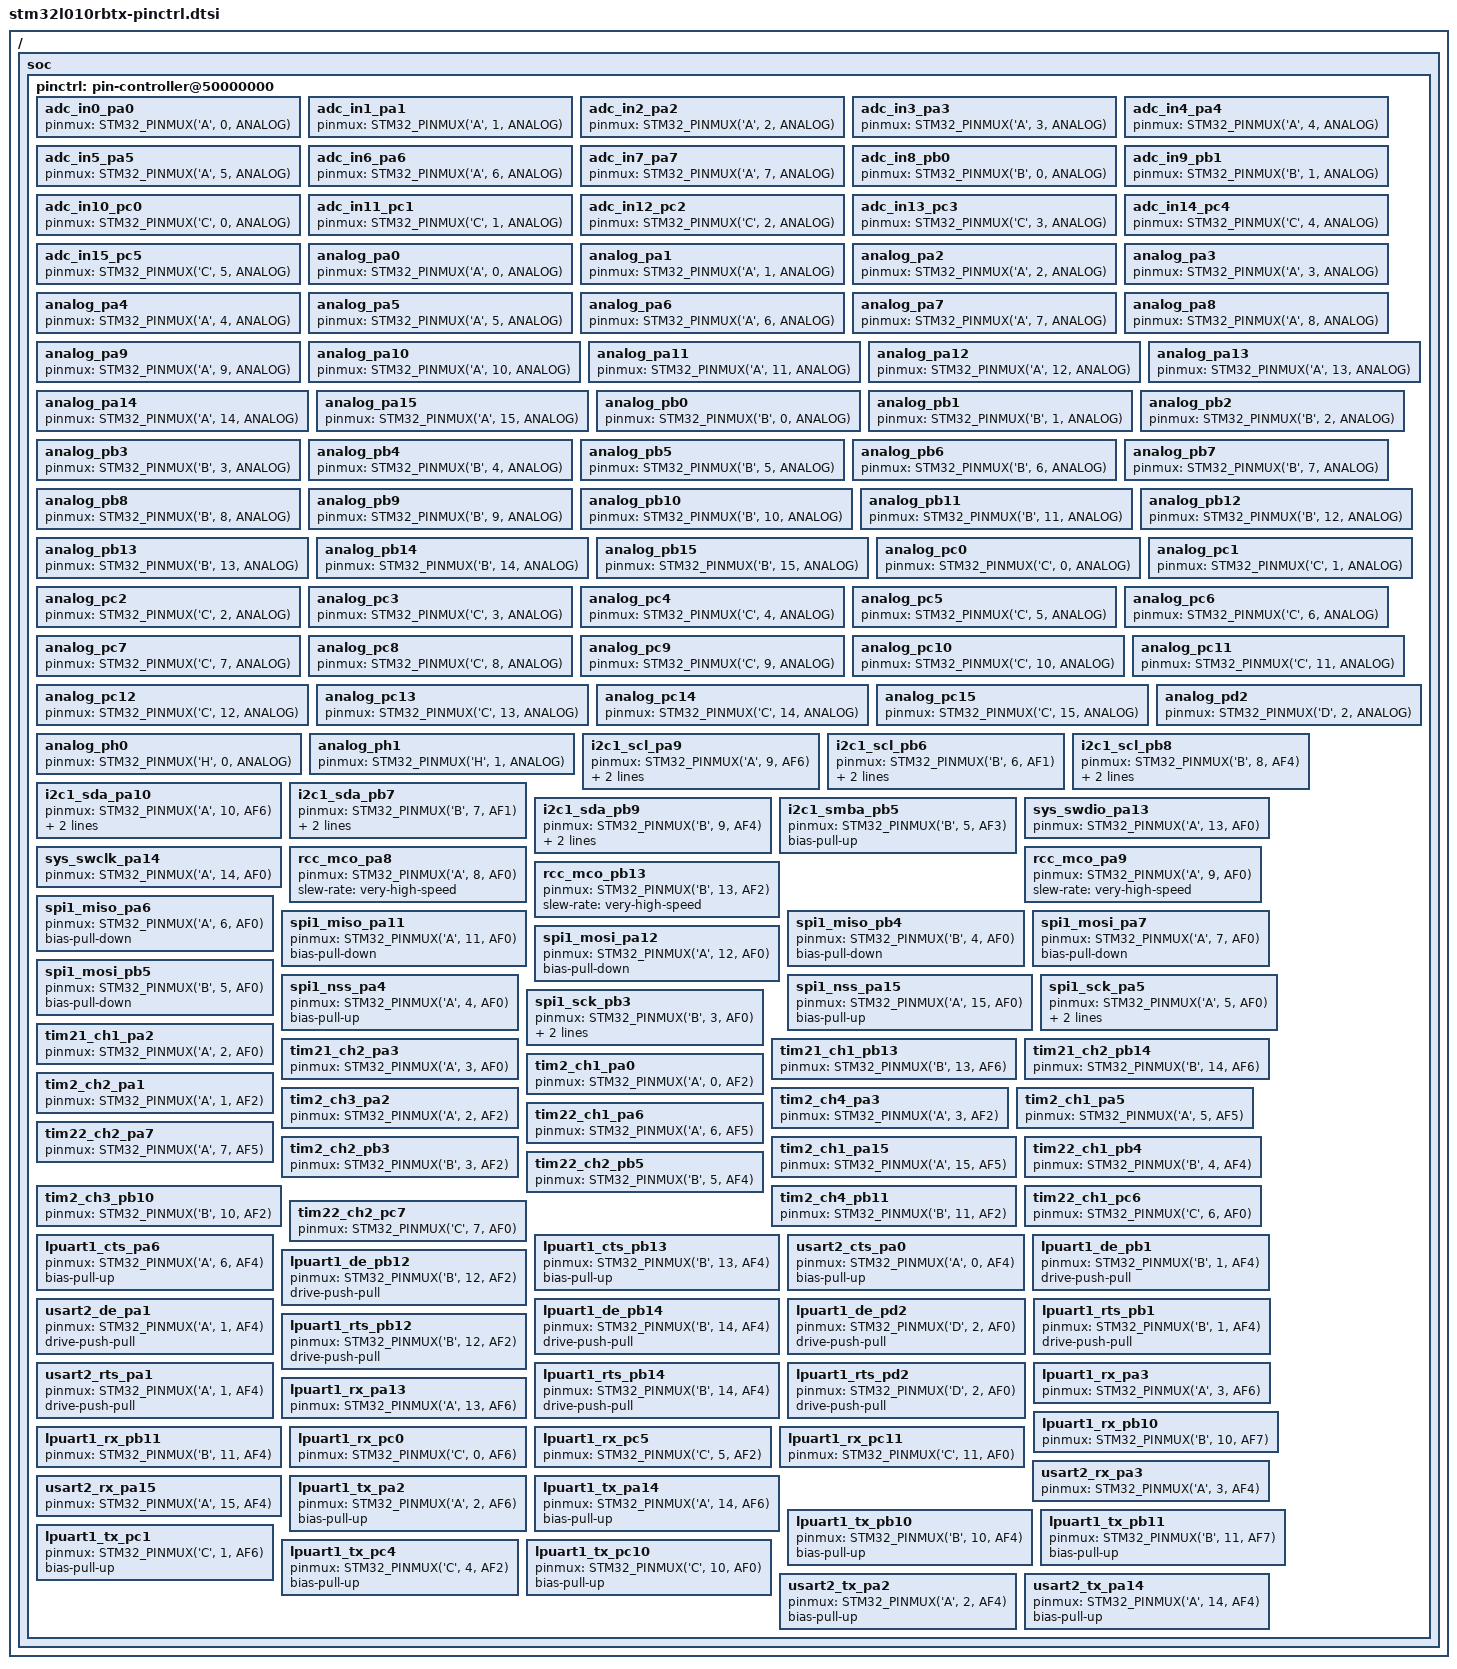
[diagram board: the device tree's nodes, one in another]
/*
 * NOTE: Autogenerated file using genpinctrl.py
 *
 * SPDX-License-Identifier: Apache-2.0
 */

#include <zephyr/dt-bindings/pinctrl/stm32-pinctrl.h>

/ {
	soc {
		pinctrl: pin-controller@50000000 {

			/* ADC_IN / ADC_INN / ADC_INP */

			/omit-if-no-ref/ adc_in0_pa0: adc_in0_pa0 {
				pinmux = <STM32_PINMUX('A', 0, ANALOG)>;
			};

			/omit-if-no-ref/ adc_in1_pa1: adc_in1_pa1 {
				pinmux = <STM32_PINMUX('A', 1, ANALOG)>;
			};

			/omit-if-no-ref/ adc_in2_pa2: adc_in2_pa2 {
				pinmux = <STM32_PINMUX('A', 2, ANALOG)>;
			};

			/omit-if-no-ref/ adc_in3_pa3: adc_in3_pa3 {
				pinmux = <STM32_PINMUX('A', 3, ANALOG)>;
			};

			/omit-if-no-ref/ adc_in4_pa4: adc_in4_pa4 {
				pinmux = <STM32_PINMUX('A', 4, ANALOG)>;
			};

			/omit-if-no-ref/ adc_in5_pa5: adc_in5_pa5 {
				pinmux = <STM32_PINMUX('A', 5, ANALOG)>;
			};

			/omit-if-no-ref/ adc_in6_pa6: adc_in6_pa6 {
				pinmux = <STM32_PINMUX('A', 6, ANALOG)>;
			};

			/omit-if-no-ref/ adc_in7_pa7: adc_in7_pa7 {
				pinmux = <STM32_PINMUX('A', 7, ANALOG)>;
			};

			/omit-if-no-ref/ adc_in8_pb0: adc_in8_pb0 {
				pinmux = <STM32_PINMUX('B', 0, ANALOG)>;
			};

			/omit-if-no-ref/ adc_in9_pb1: adc_in9_pb1 {
				pinmux = <STM32_PINMUX('B', 1, ANALOG)>;
			};

			/omit-if-no-ref/ adc_in10_pc0: adc_in10_pc0 {
				pinmux = <STM32_PINMUX('C', 0, ANALOG)>;
			};

			/omit-if-no-ref/ adc_in11_pc1: adc_in11_pc1 {
				pinmux = <STM32_PINMUX('C', 1, ANALOG)>;
			};

			/omit-if-no-ref/ adc_in12_pc2: adc_in12_pc2 {
				pinmux = <STM32_PINMUX('C', 2, ANALOG)>;
			};

			/omit-if-no-ref/ adc_in13_pc3: adc_in13_pc3 {
				pinmux = <STM32_PINMUX('C', 3, ANALOG)>;
			};

			/omit-if-no-ref/ adc_in14_pc4: adc_in14_pc4 {
				pinmux = <STM32_PINMUX('C', 4, ANALOG)>;
			};

			/omit-if-no-ref/ adc_in15_pc5: adc_in15_pc5 {
				pinmux = <STM32_PINMUX('C', 5, ANALOG)>;
			};

			/* Analog */

			/omit-if-no-ref/ analog_pa0: analog_pa0 {
				pinmux = <STM32_PINMUX('A', 0, ANALOG)>;
			};

			/omit-if-no-ref/ analog_pa1: analog_pa1 {
				pinmux = <STM32_PINMUX('A', 1, ANALOG)>;
			};

			/omit-if-no-ref/ analog_pa2: analog_pa2 {
				pinmux = <STM32_PINMUX('A', 2, ANALOG)>;
			};

			/omit-if-no-ref/ analog_pa3: analog_pa3 {
				pinmux = <STM32_PINMUX('A', 3, ANALOG)>;
			};

			/omit-if-no-ref/ analog_pa4: analog_pa4 {
				pinmux = <STM32_PINMUX('A', 4, ANALOG)>;
			};

			/omit-if-no-ref/ analog_pa5: analog_pa5 {
				pinmux = <STM32_PINMUX('A', 5, ANALOG)>;
			};

			/omit-if-no-ref/ analog_pa6: analog_pa6 {
				pinmux = <STM32_PINMUX('A', 6, ANALOG)>;
			};

			/omit-if-no-ref/ analog_pa7: analog_pa7 {
				pinmux = <STM32_PINMUX('A', 7, ANALOG)>;
			};

			/omit-if-no-ref/ analog_pa8: analog_pa8 {
				pinmux = <STM32_PINMUX('A', 8, ANALOG)>;
			};

			/omit-if-no-ref/ analog_pa9: analog_pa9 {
				pinmux = <STM32_PINMUX('A', 9, ANALOG)>;
			};

			/omit-if-no-ref/ analog_pa10: analog_pa10 {
				pinmux = <STM32_PINMUX('A', 10, ANALOG)>;
			};

			/omit-if-no-ref/ analog_pa11: analog_pa11 {
				pinmux = <STM32_PINMUX('A', 11, ANALOG)>;
			};

			/omit-if-no-ref/ analog_pa12: analog_pa12 {
				pinmux = <STM32_PINMUX('A', 12, ANALOG)>;
			};

			/omit-if-no-ref/ analog_pa13: analog_pa13 {
				pinmux = <STM32_PINMUX('A', 13, ANALOG)>;
			};

			/omit-if-no-ref/ analog_pa14: analog_pa14 {
				pinmux = <STM32_PINMUX('A', 14, ANALOG)>;
			};

			/omit-if-no-ref/ analog_pa15: analog_pa15 {
				pinmux = <STM32_PINMUX('A', 15, ANALOG)>;
			};

			/omit-if-no-ref/ analog_pb0: analog_pb0 {
				pinmux = <STM32_PINMUX('B', 0, ANALOG)>;
			};

			/omit-if-no-ref/ analog_pb1: analog_pb1 {
				pinmux = <STM32_PINMUX('B', 1, ANALOG)>;
			};

			/omit-if-no-ref/ analog_pb2: analog_pb2 {
				pinmux = <STM32_PINMUX('B', 2, ANALOG)>;
			};

			/omit-if-no-ref/ analog_pb3: analog_pb3 {
				pinmux = <STM32_PINMUX('B', 3, ANALOG)>;
			};

			/omit-if-no-ref/ analog_pb4: analog_pb4 {
				pinmux = <STM32_PINMUX('B', 4, ANALOG)>;
			};

			/omit-if-no-ref/ analog_pb5: analog_pb5 {
				pinmux = <STM32_PINMUX('B', 5, ANALOG)>;
			};

			/omit-if-no-ref/ analog_pb6: analog_pb6 {
				pinmux = <STM32_PINMUX('B', 6, ANALOG)>;
			};

			/omit-if-no-ref/ analog_pb7: analog_pb7 {
				pinmux = <STM32_PINMUX('B', 7, ANALOG)>;
			};

			/omit-if-no-ref/ analog_pb8: analog_pb8 {
				pinmux = <STM32_PINMUX('B', 8, ANALOG)>;
			};

			/omit-if-no-ref/ analog_pb9: analog_pb9 {
				pinmux = <STM32_PINMUX('B', 9, ANALOG)>;
			};

			/omit-if-no-ref/ analog_pb10: analog_pb10 {
				pinmux = <STM32_PINMUX('B', 10, ANALOG)>;
			};

			/omit-if-no-ref/ analog_pb11: analog_pb11 {
				pinmux = <STM32_PINMUX('B', 11, ANALOG)>;
			};

			/omit-if-no-ref/ analog_pb12: analog_pb12 {
				pinmux = <STM32_PINMUX('B', 12, ANALOG)>;
			};

			/omit-if-no-ref/ analog_pb13: analog_pb13 {
				pinmux = <STM32_PINMUX('B', 13, ANALOG)>;
			};

			/omit-if-no-ref/ analog_pb14: analog_pb14 {
				pinmux = <STM32_PINMUX('B', 14, ANALOG)>;
			};

			/omit-if-no-ref/ analog_pb15: analog_pb15 {
				pinmux = <STM32_PINMUX('B', 15, ANALOG)>;
			};

			/omit-if-no-ref/ analog_pc0: analog_pc0 {
				pinmux = <STM32_PINMUX('C', 0, ANALOG)>;
			};

			/omit-if-no-ref/ analog_pc1: analog_pc1 {
				pinmux = <STM32_PINMUX('C', 1, ANALOG)>;
			};

			/omit-if-no-ref/ analog_pc2: analog_pc2 {
				pinmux = <STM32_PINMUX('C', 2, ANALOG)>;
			};

			/omit-if-no-ref/ analog_pc3: analog_pc3 {
				pinmux = <STM32_PINMUX('C', 3, ANALOG)>;
			};

			/omit-if-no-ref/ analog_pc4: analog_pc4 {
				pinmux = <STM32_PINMUX('C', 4, ANALOG)>;
			};

			/omit-if-no-ref/ analog_pc5: analog_pc5 {
				pinmux = <STM32_PINMUX('C', 5, ANALOG)>;
			};

			/omit-if-no-ref/ analog_pc6: analog_pc6 {
				pinmux = <STM32_PINMUX('C', 6, ANALOG)>;
			};

			/omit-if-no-ref/ analog_pc7: analog_pc7 {
				pinmux = <STM32_PINMUX('C', 7, ANALOG)>;
			};

			/omit-if-no-ref/ analog_pc8: analog_pc8 {
				pinmux = <STM32_PINMUX('C', 8, ANALOG)>;
			};

			/omit-if-no-ref/ analog_pc9: analog_pc9 {
				pinmux = <STM32_PINMUX('C', 9, ANALOG)>;
			};

			/omit-if-no-ref/ analog_pc10: analog_pc10 {
				pinmux = <STM32_PINMUX('C', 10, ANALOG)>;
			};

			/omit-if-no-ref/ analog_pc11: analog_pc11 {
				pinmux = <STM32_PINMUX('C', 11, ANALOG)>;
			};

			/omit-if-no-ref/ analog_pc12: analog_pc12 {
				pinmux = <STM32_PINMUX('C', 12, ANALOG)>;
			};

			/omit-if-no-ref/ analog_pc13: analog_pc13 {
				pinmux = <STM32_PINMUX('C', 13, ANALOG)>;
			};

			/omit-if-no-ref/ analog_pc14: analog_pc14 {
				pinmux = <STM32_PINMUX('C', 14, ANALOG)>;
			};

			/omit-if-no-ref/ analog_pc15: analog_pc15 {
				pinmux = <STM32_PINMUX('C', 15, ANALOG)>;
			};

			/omit-if-no-ref/ analog_pd2: analog_pd2 {
				pinmux = <STM32_PINMUX('D', 2, ANALOG)>;
			};

			/omit-if-no-ref/ analog_ph0: analog_ph0 {
				pinmux = <STM32_PINMUX('H', 0, ANALOG)>;
			};

			/omit-if-no-ref/ analog_ph1: analog_ph1 {
				pinmux = <STM32_PINMUX('H', 1, ANALOG)>;
			};

			/* I2C_SCL */

			/omit-if-no-ref/ i2c1_scl_pa9: i2c1_scl_pa9 {
				pinmux = <STM32_PINMUX('A', 9, AF6)>;
				bias-pull-up;
				drive-open-drain;
			};

			/omit-if-no-ref/ i2c1_scl_pb6: i2c1_scl_pb6 {
				pinmux = <STM32_PINMUX('B', 6, AF1)>;
				bias-pull-up;
				drive-open-drain;
			};

			/omit-if-no-ref/ i2c1_scl_pb8: i2c1_scl_pb8 {
				pinmux = <STM32_PINMUX('B', 8, AF4)>;
				bias-pull-up;
				drive-open-drain;
			};

			/* I2C_SDA */

			/omit-if-no-ref/ i2c1_sda_pa10: i2c1_sda_pa10 {
				pinmux = <STM32_PINMUX('A', 10, AF6)>;
				bias-pull-up;
				drive-open-drain;
			};

			/omit-if-no-ref/ i2c1_sda_pb7: i2c1_sda_pb7 {
				pinmux = <STM32_PINMUX('B', 7, AF1)>;
				bias-pull-up;
				drive-open-drain;
			};

			/omit-if-no-ref/ i2c1_sda_pb9: i2c1_sda_pb9 {
				pinmux = <STM32_PINMUX('B', 9, AF4)>;
				bias-pull-up;
				drive-open-drain;
			};

			/* I2C_SMBA */

			/omit-if-no-ref/ i2c1_smba_pb5: i2c1_smba_pb5 {
				pinmux = <STM32_PINMUX('B', 5, AF3)>;
				bias-pull-up;
			};

			/* JTAG PORT */

			/omit-if-no-ref/ sys_swdio_pa13: sys_swdio_pa13 {
				pinmux = <STM32_PINMUX('A', 13, AF0)>;
			};

			/omit-if-no-ref/ sys_swclk_pa14: sys_swclk_pa14 {
				pinmux = <STM32_PINMUX('A', 14, AF0)>;
			};

			/* RCC_MCO */

			/omit-if-no-ref/ rcc_mco_pa8: rcc_mco_pa8 {
				pinmux = <STM32_PINMUX('A', 8, AF0)>;
				slew-rate = "very-high-speed";
			};

			/omit-if-no-ref/ rcc_mco_pa9: rcc_mco_pa9 {
				pinmux = <STM32_PINMUX('A', 9, AF0)>;
				slew-rate = "very-high-speed";
			};

			/omit-if-no-ref/ rcc_mco_pb13: rcc_mco_pb13 {
				pinmux = <STM32_PINMUX('B', 13, AF2)>;
				slew-rate = "very-high-speed";
			};

			/* SPI_MISO */

			/omit-if-no-ref/ spi1_miso_pa6: spi1_miso_pa6 {
				pinmux = <STM32_PINMUX('A', 6, AF0)>;
				bias-pull-down;
			};

			/omit-if-no-ref/ spi1_miso_pa11: spi1_miso_pa11 {
				pinmux = <STM32_PINMUX('A', 11, AF0)>;
				bias-pull-down;
			};

			/omit-if-no-ref/ spi1_miso_pb4: spi1_miso_pb4 {
				pinmux = <STM32_PINMUX('B', 4, AF0)>;
				bias-pull-down;
			};

			/* SPI_MOSI */

			/omit-if-no-ref/ spi1_mosi_pa7: spi1_mosi_pa7 {
				pinmux = <STM32_PINMUX('A', 7, AF0)>;
				bias-pull-down;
			};

			/omit-if-no-ref/ spi1_mosi_pa12: spi1_mosi_pa12 {
				pinmux = <STM32_PINMUX('A', 12, AF0)>;
				bias-pull-down;
			};

			/omit-if-no-ref/ spi1_mosi_pb5: spi1_mosi_pb5 {
				pinmux = <STM32_PINMUX('B', 5, AF0)>;
				bias-pull-down;
			};

			/* SPI_NSS */

			/omit-if-no-ref/ spi1_nss_pa4: spi1_nss_pa4 {
				pinmux = <STM32_PINMUX('A', 4, AF0)>;
				bias-pull-up;
			};

			/omit-if-no-ref/ spi1_nss_pa15: spi1_nss_pa15 {
				pinmux = <STM32_PINMUX('A', 15, AF0)>;
				bias-pull-up;
			};

			/* SPI_SCK */

			/omit-if-no-ref/ spi1_sck_pa5: spi1_sck_pa5 {
				pinmux = <STM32_PINMUX('A', 5, AF0)>;
				bias-pull-down;
				slew-rate = "very-high-speed";
			};

			/omit-if-no-ref/ spi1_sck_pb3: spi1_sck_pb3 {
				pinmux = <STM32_PINMUX('B', 3, AF0)>;
				bias-pull-down;
				slew-rate = "very-high-speed";
			};

			/* TIM_CH / TIM_CHN */

			/omit-if-no-ref/ tim21_ch1_pa2: tim21_ch1_pa2 {
				pinmux = <STM32_PINMUX('A', 2, AF0)>;
			};

			/omit-if-no-ref/ tim21_ch2_pa3: tim21_ch2_pa3 {
				pinmux = <STM32_PINMUX('A', 3, AF0)>;
			};

			/omit-if-no-ref/ tim21_ch1_pb13: tim21_ch1_pb13 {
				pinmux = <STM32_PINMUX('B', 13, AF6)>;
			};

			/omit-if-no-ref/ tim21_ch2_pb14: tim21_ch2_pb14 {
				pinmux = <STM32_PINMUX('B', 14, AF6)>;
			};

			/omit-if-no-ref/ tim2_ch1_pa0: tim2_ch1_pa0 {
				pinmux = <STM32_PINMUX('A', 0, AF2)>;
			};

			/omit-if-no-ref/ tim2_ch2_pa1: tim2_ch2_pa1 {
				pinmux = <STM32_PINMUX('A', 1, AF2)>;
			};

			/omit-if-no-ref/ tim2_ch3_pa2: tim2_ch3_pa2 {
				pinmux = <STM32_PINMUX('A', 2, AF2)>;
			};

			/omit-if-no-ref/ tim2_ch4_pa3: tim2_ch4_pa3 {
				pinmux = <STM32_PINMUX('A', 3, AF2)>;
			};

			/omit-if-no-ref/ tim2_ch1_pa5: tim2_ch1_pa5 {
				pinmux = <STM32_PINMUX('A', 5, AF5)>;
			};

			/omit-if-no-ref/ tim22_ch1_pa6: tim22_ch1_pa6 {
				pinmux = <STM32_PINMUX('A', 6, AF5)>;
			};

			/omit-if-no-ref/ tim22_ch2_pa7: tim22_ch2_pa7 {
				pinmux = <STM32_PINMUX('A', 7, AF5)>;
			};

			/omit-if-no-ref/ tim2_ch1_pa15: tim2_ch1_pa15 {
				pinmux = <STM32_PINMUX('A', 15, AF5)>;
			};

			/omit-if-no-ref/ tim2_ch2_pb3: tim2_ch2_pb3 {
				pinmux = <STM32_PINMUX('B', 3, AF2)>;
			};

			/omit-if-no-ref/ tim22_ch1_pb4: tim22_ch1_pb4 {
				pinmux = <STM32_PINMUX('B', 4, AF4)>;
			};

			/omit-if-no-ref/ tim22_ch2_pb5: tim22_ch2_pb5 {
				pinmux = <STM32_PINMUX('B', 5, AF4)>;
			};

			/omit-if-no-ref/ tim2_ch3_pb10: tim2_ch3_pb10 {
				pinmux = <STM32_PINMUX('B', 10, AF2)>;
			};

			/omit-if-no-ref/ tim2_ch4_pb11: tim2_ch4_pb11 {
				pinmux = <STM32_PINMUX('B', 11, AF2)>;
			};

			/omit-if-no-ref/ tim22_ch1_pc6: tim22_ch1_pc6 {
				pinmux = <STM32_PINMUX('C', 6, AF0)>;
			};

			/omit-if-no-ref/ tim22_ch2_pc7: tim22_ch2_pc7 {
				pinmux = <STM32_PINMUX('C', 7, AF0)>;
			};

			/* UART_CTS / USART_CTS / LPUART_CTS */

			/omit-if-no-ref/ lpuart1_cts_pa6: lpuart1_cts_pa6 {
				pinmux = <STM32_PINMUX('A', 6, AF4)>;
				bias-pull-up;
			};

			/omit-if-no-ref/ lpuart1_cts_pb13: lpuart1_cts_pb13 {
				pinmux = <STM32_PINMUX('B', 13, AF4)>;
				bias-pull-up;
			};

			/omit-if-no-ref/ usart2_cts_pa0: usart2_cts_pa0 {
				pinmux = <STM32_PINMUX('A', 0, AF4)>;
				bias-pull-up;
			};

			/* UART_DE / USART_DE / LPUART_DE */

			/omit-if-no-ref/ lpuart1_de_pb1: lpuart1_de_pb1 {
				pinmux = <STM32_PINMUX('B', 1, AF4)>;
				drive-push-pull;
			};

			/omit-if-no-ref/ lpuart1_de_pb12: lpuart1_de_pb12 {
				pinmux = <STM32_PINMUX('B', 12, AF2)>;
				drive-push-pull;
			};

			/omit-if-no-ref/ lpuart1_de_pb14: lpuart1_de_pb14 {
				pinmux = <STM32_PINMUX('B', 14, AF4)>;
				drive-push-pull;
			};

			/omit-if-no-ref/ lpuart1_de_pd2: lpuart1_de_pd2 {
				pinmux = <STM32_PINMUX('D', 2, AF0)>;
				drive-push-pull;
			};

			/omit-if-no-ref/ usart2_de_pa1: usart2_de_pa1 {
				pinmux = <STM32_PINMUX('A', 1, AF4)>;
				drive-push-pull;
			};

			/* UART_RTS / USART_RTS / LPUART_RTS */

			/omit-if-no-ref/ lpuart1_rts_pb1: lpuart1_rts_pb1 {
				pinmux = <STM32_PINMUX('B', 1, AF4)>;
				drive-push-pull;
			};

			/omit-if-no-ref/ lpuart1_rts_pb12: lpuart1_rts_pb12 {
				pinmux = <STM32_PINMUX('B', 12, AF2)>;
				drive-push-pull;
			};

			/omit-if-no-ref/ lpuart1_rts_pb14: lpuart1_rts_pb14 {
				pinmux = <STM32_PINMUX('B', 14, AF4)>;
				drive-push-pull;
			};

			/omit-if-no-ref/ lpuart1_rts_pd2: lpuart1_rts_pd2 {
				pinmux = <STM32_PINMUX('D', 2, AF0)>;
				drive-push-pull;
			};

			/omit-if-no-ref/ usart2_rts_pa1: usart2_rts_pa1 {
				pinmux = <STM32_PINMUX('A', 1, AF4)>;
				drive-push-pull;
			};

			/* UART_RX / USART_RX / LPUART_RX */

			/omit-if-no-ref/ lpuart1_rx_pa3: lpuart1_rx_pa3 {
				pinmux = <STM32_PINMUX('A', 3, AF6)>;
			};

			/omit-if-no-ref/ lpuart1_rx_pa13: lpuart1_rx_pa13 {
				pinmux = <STM32_PINMUX('A', 13, AF6)>;
			};

			/omit-if-no-ref/ lpuart1_rx_pb10: lpuart1_rx_pb10 {
				pinmux = <STM32_PINMUX('B', 10, AF7)>;
			};

			/omit-if-no-ref/ lpuart1_rx_pb11: lpuart1_rx_pb11 {
				pinmux = <STM32_PINMUX('B', 11, AF4)>;
			};

			/omit-if-no-ref/ lpuart1_rx_pc0: lpuart1_rx_pc0 {
				pinmux = <STM32_PINMUX('C', 0, AF6)>;
			};

			/omit-if-no-ref/ lpuart1_rx_pc5: lpuart1_rx_pc5 {
				pinmux = <STM32_PINMUX('C', 5, AF2)>;
			};

			/omit-if-no-ref/ lpuart1_rx_pc11: lpuart1_rx_pc11 {
				pinmux = <STM32_PINMUX('C', 11, AF0)>;
			};

			/omit-if-no-ref/ usart2_rx_pa3: usart2_rx_pa3 {
				pinmux = <STM32_PINMUX('A', 3, AF4)>;
			};

			/omit-if-no-ref/ usart2_rx_pa15: usart2_rx_pa15 {
				pinmux = <STM32_PINMUX('A', 15, AF4)>;
			};

			/* UART_TX / USART_TX / LPUART_TX */

			/omit-if-no-ref/ lpuart1_tx_pa2: lpuart1_tx_pa2 {
				pinmux = <STM32_PINMUX('A', 2, AF6)>;
				bias-pull-up;
			};

			/omit-if-no-ref/ lpuart1_tx_pa14: lpuart1_tx_pa14 {
				pinmux = <STM32_PINMUX('A', 14, AF6)>;
				bias-pull-up;
			};

			/omit-if-no-ref/ lpuart1_tx_pb10: lpuart1_tx_pb10 {
				pinmux = <STM32_PINMUX('B', 10, AF4)>;
				bias-pull-up;
			};

			/omit-if-no-ref/ lpuart1_tx_pb11: lpuart1_tx_pb11 {
				pinmux = <STM32_PINMUX('B', 11, AF7)>;
				bias-pull-up;
			};

			/omit-if-no-ref/ lpuart1_tx_pc1: lpuart1_tx_pc1 {
				pinmux = <STM32_PINMUX('C', 1, AF6)>;
				bias-pull-up;
			};

			/omit-if-no-ref/ lpuart1_tx_pc4: lpuart1_tx_pc4 {
				pinmux = <STM32_PINMUX('C', 4, AF2)>;
				bias-pull-up;
			};

			/omit-if-no-ref/ lpuart1_tx_pc10: lpuart1_tx_pc10 {
				pinmux = <STM32_PINMUX('C', 10, AF0)>;
				bias-pull-up;
			};

			/omit-if-no-ref/ usart2_tx_pa2: usart2_tx_pa2 {
				pinmux = <STM32_PINMUX('A', 2, AF4)>;
				bias-pull-up;
			};

			/omit-if-no-ref/ usart2_tx_pa14: usart2_tx_pa14 {
				pinmux = <STM32_PINMUX('A', 14, AF4)>;
				bias-pull-up;
			};

		};
	};
};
